AUTOSAR XML (schema 00052)
package /Components
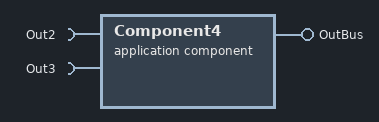
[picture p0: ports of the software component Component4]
  application sw component type Component4
    require port Out2
    require port Out3
    provide port OutBus
